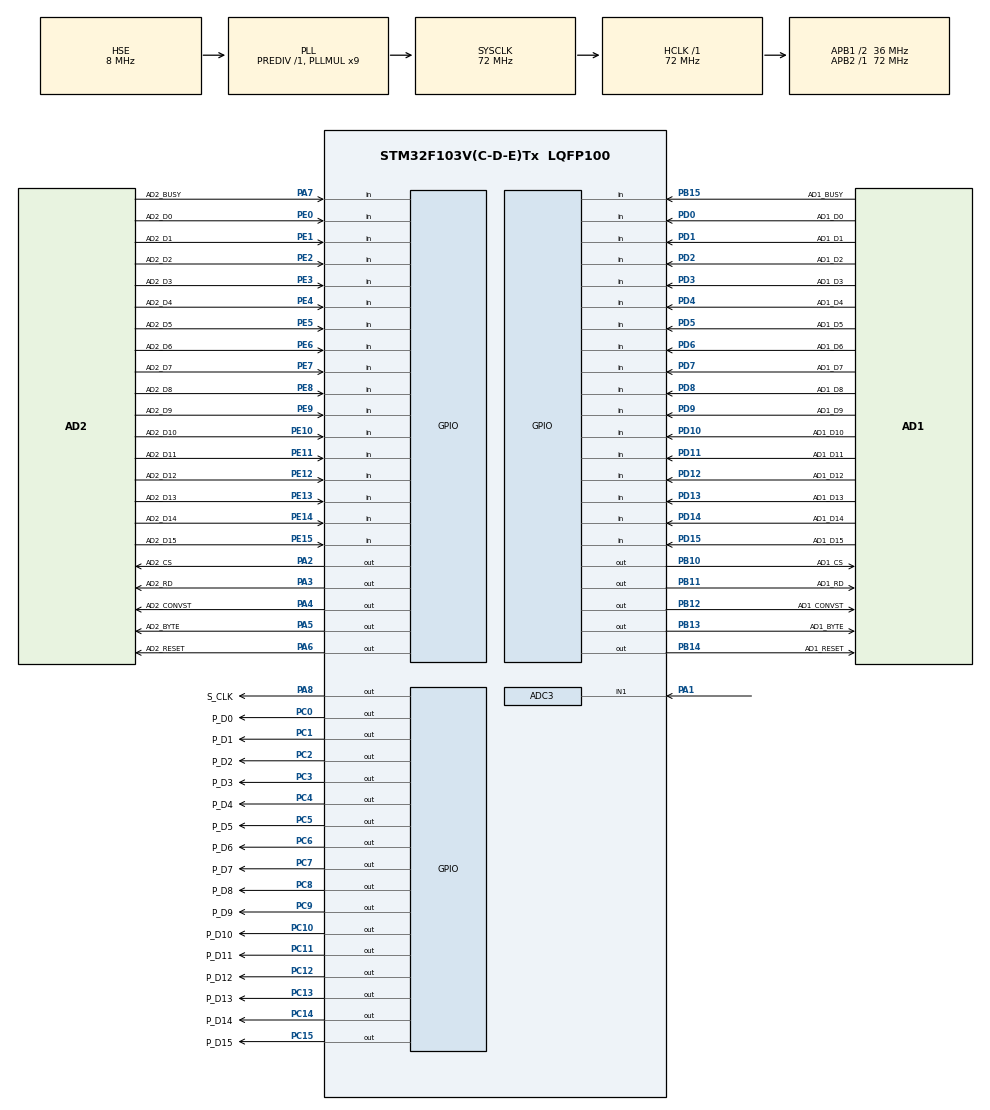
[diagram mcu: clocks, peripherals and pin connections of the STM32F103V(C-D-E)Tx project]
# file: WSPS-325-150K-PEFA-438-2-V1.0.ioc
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ADC3.Channel-0\#ChannelRegularConversion=ADC_CHANNEL_1
ADC3.NbrOfConversionFlag=1
ADC3.Rank-0\#ChannelRegularConversion=1
ADC3.SamplingTime-0\#ChannelRegularConversion=ADC_SAMPLETIME_1CYCLE_5
Mcu.Family=STM32F1
Mcu.Name=STM32F103V(C-D-E)Tx
Mcu.Package=LQFP100
NVIC.ADC3_IRQn=true\:1\:0\:true\:false\:true\:true\:true
NVIC.PriorityGroup=NVIC_PRIORITYGROUP_2
NVIC.TIM1_BRK_IRQn=true\:0\:0\:false\:false\:true\:true\:true
NVIC.TIM1_CC_IRQn=true\:0\:0\:false\:false\:true\:true\:true
NVIC.TIM1_TRG_COM_IRQn=true\:0\:0\:false\:false\:true\:true\:true
NVIC.TIM1_UP_IRQn=true\:0\:0\:false\:false\:true\:true\:true
NVIC.TIM3_IRQn=true\:3\:0\:true\:false\:true\:true\:true
OSC_IN.Mode=HSE-External-Oscillator
OSC_IN.Signal=RCC_OSC_IN
OSC_OUT.Mode=HSE-External-Oscillator
OSC_OUT.Signal=RCC_OSC_OUT
PA1.Signal=ADCx_IN1
PA13.Mode=Serial_Wire
PA13.Signal=SYS_JTMS-SWDIO
PA14.Mode=Serial_Wire
PA14.Signal=SYS_JTCK-SWCLK
PA2.GPIO_Label=AD2_CS
PA2.Signal=GPIO_Output
PA3.GPIO_Label=AD2_RD
PA3.Signal=GPIO_Output
PA4.GPIO_Label=AD2_CONVST
PA4.Signal=GPIO_Output
PA5.GPIO_Label=AD2_BYTE
PA5.Signal=GPIO_Output
PA6.GPIO_Label=AD2_RESET
PA6.Signal=GPIO_Output
PA7.GPIO_Label=AD2_BUSY
PA7.Signal=GPIO_Input
PA8.GPIO_Label=S_CLK
PA8.Signal=GPIO_Output
PB10.GPIO_Label=AD1_CS
PB10.Signal=GPIO_Output
PB11.GPIO_Label=AD1_RD
PB11.Signal=GPIO_Output
PB12.GPIO_Label=AD1_CONVST
PB12.Signal=GPIO_Output
PB13.GPIO_Label=AD1_BYTE
PB13.Signal=GPIO_Output
PB14.GPIO_Label=AD1_RESET
PB14.Signal=GPIO_Output
PB15.GPIO_Label=AD1_BUSY
PB15.Signal=GPIO_Input
PC0.GPIO_Label=P_D0
PC0.Signal=GPIO_Output
PC1.GPIO_Label=P_D1
PC1.Signal=GPIO_Output
PC10.GPIO_Label=P_D10
PC10.Signal=GPIO_Output
PC11.GPIO_Label=P_D11
PC11.Signal=GPIO_Output
PC12.GPIO_Label=P_D12
PC12.Signal=GPIO_Output
PC13-TAMPER-RTC.GPIO_Label=P_D13
PC13-TAMPER-RTC.Signal=GPIO_Output
PC14-OSC32_IN.GPIO_Label=P_D14
PC14-OSC32_IN.Signal=GPIO_Output
PC15-OSC32_OUT.GPIO_Label=P_D15
PC15-OSC32_OUT.Signal=GPIO_Output
PC2.GPIO_Label=P_D2
PC2.Signal=GPIO_Output
PC3.GPIO_Label=P_D3
PC3.Signal=GPIO_Output
PC4.GPIO_Label=P_D4
PC4.Signal=GPIO_Output
PC5.GPIO_Label=P_D5
PC5.Signal=GPIO_Output
PC6.GPIO_Label=P_D6
PC6.Signal=GPIO_Output
PC7.GPIO_Label=P_D7
PC7.Signal=GPIO_Output
PC8.GPIO_Label=P_D8
PC8.Signal=GPIO_Output
PC9.GPIO_Label=P_D9
PC9.Signal=GPIO_Output
PD0.GPIO_Label=AD1_D0
PD0.Signal=GPIO_Input
PD1.GPIO_Label=AD1_D1
PD1.Signal=GPIO_Input
PD10.GPIO_Label=AD1_D10
PD10.Signal=GPIO_Input
PD11.GPIO_Label=AD1_D11
PD11.Signal=GPIO_Input
PD12.GPIO_Label=AD1_D12
PD12.Signal=GPIO_Input
PD13.GPIO_Label=AD1_D13
PD13.Signal=GPIO_Input
PD14.GPIO_Label=AD1_D14
PD14.Signal=GPIO_Input
PD15.GPIO_Label=AD1_D15
PD15.Signal=GPIO_Input
PD2.GPIO_Label=AD1_D2
PD2.Signal=GPIO_Input
PD3.GPIO_Label=AD1_D3
PD3.Signal=GPIO_Input
PD4.GPIO_Label=AD1_D4
PD4.Signal=GPIO_Input
PD5.GPIO_Label=AD1_D5
PD5.Signal=GPIO_Input
PD6.GPIO_Label=AD1_D6
PD6.Signal=GPIO_Input
PD7.GPIO_Label=AD1_D7
PD7.Signal=GPIO_Input
PD8.GPIO_Label=AD1_D8
PD8.Signal=GPIO_Input
PD9.GPIO_Label=AD1_D9
PD9.Signal=GPIO_Input
PE0.GPIO_Label=AD2_D0
PE0.Signal=GPIO_Input
PE1.GPIO_Label=AD2_D1
PE1.Signal=GPIO_Input
PE10.GPIO_Label=AD2_D10
PE10.Signal=GPIO_Input
PE11.GPIO_Label=AD2_D11
PE11.Signal=GPIO_Input
PE12.GPIO_Label=AD2_D12
PE12.Signal=GPIO_Input
PE13.GPIO_Label=AD2_D13
PE13.Signal=GPIO_Input
PE14.GPIO_Label=AD2_D14
PE14.Signal=GPIO_Input
PE15.GPIO_Label=AD2_D15
PE15.Signal=GPIO_Input
PE2.GPIO_Label=AD2_D2
PE2.Signal=GPIO_Input
PE3.GPIO_Label=AD2_D3
PE3.Signal=GPIO_Input
PE4.GPIO_Label=AD2_D4
PE4.Signal=GPIO_Input
PE5.GPIO_Label=AD2_D5
PE5.Signal=GPIO_Input
PE6.GPIO_Label=AD2_D6
PE6.Signal=GPIO_Input
PE7.GPIO_Label=AD2_D7
PE7.Signal=GPIO_Input
PE8.GPIO_Label=AD2_D8
PE8.Signal=GPIO_Input
PE9.GPIO_Label=AD2_D9
PE9.Signal=GPIO_Input
ProjectManager.HeapSize=0x200
ProjectManager.StackSize=0x400
ProjectManager.TargetToolchain=MDK-ARM V5.32
RCC.ADCPresc=RCC_ADCPCLK2_DIV6
RCC.AHBFreq_Value=72000000
RCC.APB1CLKDivider=RCC_HCLK_DIV2
RCC.APB1Freq_Value=36000000
RCC.APB1TimFreq_Value=72000000
RCC.APB2Freq_Value=72000000
RCC.APB2TimFreq_Value=72000000
RCC.HCLKFreq_Value=72000000
RCC.PLLMUL=RCC_PLL_MUL9
RCC.PLLSourceVirtual=RCC_PLLSOURCE_HSE
RCC.SYSCLKFreq_VALUE=72000000
RCC.SYSCLKSource=RCC_SYSCLKSOURCE_PLLCLK
RCC.USBFreq_Value=72000000
SH.ADCx_IN1.0=ADC3_IN1,IN1
TIM1.Channel-PWM\ Generation4\ No\ Output=TIM_CHANNEL_4
VP_TIM1_VS_no_output4.Mode=PWM Generation4 No Output
VP_TIM3_VS_ClockSourceINT.Mode=Internal
board=custom

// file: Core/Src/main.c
/* USER CODE BEGIN Header */
/**
  ******************************************************************************
  * @file           : main.c
  * @brief          : Main program body
  ******************************************************************************
  * @attention
  *
  * <h2><center>&copy; Copyright (c) 2022 STMicroelectronics.
  * All rights reserved.</center></h2>
  *
  * This software component is licensed by ST under BSD 3-Clause license,
  * the "License"; You may not use this file except in compliance with the
  * License. You may obtain a copy of the License at:
  *                        opensource.org/licenses/BSD-3-Clause
  *
  ******************************************************************************
  */
/* USER CODE END Header */
#include "main.h"
#include "adc.h"
#include "tim.h"
#include "gpio.h"

/* USER CODE BEGIN Includes */
#include "../../App/task.h"
#include "../../App/ads8411.h"
/* USER CODE END Includes */

void SystemClock_Config(void);

int main(void)
{

  /* MCU Configuration--------------------------------------------------------*/

  /* Reset of all peripherals, Initializes the Flash interface and the Systick. */
  HAL_Init();

  /* Configure the system clock */
  SystemClock_Config();

  /* Initialize all configured peripherals */
  MX_GPIO_Init();
  MX_ADC3_Init();
  MX_TIM3_Init();
  MX_TIM1_Init();
  /* USER CODE BEGIN 2 */
    ads8411_reset_A();
    ads8411_reset_B();

  /* USER CODE END 2 */

  /* Infinite loop */
  while (1)
  {

    /* USER CODE BEGIN 3 */
    Task_Get_Ads8411_Data();
    Task_Ads8411_Send_Data();
  }
  /* USER CODE END 3 */
}

void SystemClock_Config(void)
{
  RCC_OscInitTypeDef RCC_OscInitStruct = {0};
  RCC_ClkInitTypeDef RCC_ClkInitStruct = {0};
  RCC_PeriphCLKInitTypeDef PeriphClkInit = {0};

  /** Initializes the RCC Oscillators according to the specified parameters
  * in the RCC_OscInitTypeDef structure.
  */
  RCC_OscInitStruct.OscillatorType = RCC_OSCILLATORTYPE_HSE;
  RCC_OscInitStruct.HSEState = RCC_HSE_ON;
  RCC_OscInitStruct.HSEPredivValue = RCC_HSE_PREDIV_DIV1;
  RCC_OscInitStruct.HSIState = RCC_HSI_ON;
  RCC_OscInitStruct.PLL.PLLState = RCC_PLL_ON;
  RCC_OscInitStruct.PLL.PLLSource = RCC_PLLSOURCE_HSE;
  RCC_OscInitStruct.PLL.PLLMUL = RCC_PLL_MUL9;
  if (HAL_RCC_OscConfig(&RCC_OscInitStruct) != HAL_OK)
  {
    Error_Handler();
  }
  /** Initializes the CPU, AHB and APB buses clocks
  */
  RCC_ClkInitStruct.ClockType = RCC_CLOCKTYPE_HCLK|RCC_CLOCKTYPE_SYSCLK
                              |RCC_CLOCKTYPE_PCLK1|RCC_CLOCKTYPE_PCLK2;
  RCC_ClkInitStruct.SYSCLKSource = RCC_SYSCLKSOURCE_PLLCLK;
  RCC_ClkInitStruct.AHBCLKDivider = RCC_SYSCLK_DIV1;
  RCC_ClkInitStruct.APB1CLKDivider = RCC_HCLK_DIV2;
  RCC_ClkInitStruct.APB2CLKDivider = RCC_HCLK_DIV1;

  if (HAL_RCC_ClockConfig(&RCC_ClkInitStruct, FLASH_LATENCY_2) != HAL_OK)
  {
    Error_Handler();
  }
  PeriphClkInit.PeriphClockSelection = RCC_PERIPHCLK_ADC;
  PeriphClkInit.AdcClockSelection = RCC_ADCPCLK2_DIV6;
  if (HAL_RCCEx_PeriphCLKConfig(&PeriphClkInit) != HAL_OK)
  {
    Error_Handler();
  }
}

void Error_Handler(void)
{
  __disable_irq();
  while (1)
  {
  }
}

/************************ (C) COPYRIGHT STMicroelectronics *****END OF FILE****/
